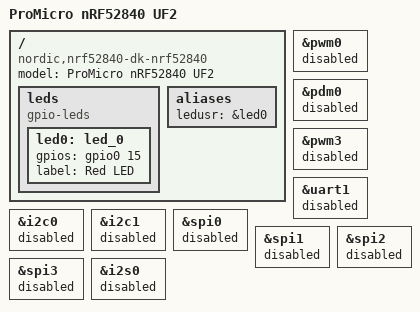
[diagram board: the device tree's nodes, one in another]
// #include <zephyr/dt-bindings/pinctrl/nrf-pinctrl.h>
// #include <nordic/nrf52840_qiaa.dtsi>

/ {
    model = "ProMicro nRF52840 UF2";
    compatible = "nordic,nrf52840-dk-nrf52840";

    leds {
        compatible = "gpio-leds";

        led0: led_0 {
            gpios = <&gpio0 15 GPIO_ACTIVE_HIGH>;
            label = "Red LED";
        };
    };

    aliases {
        ledusr = &led0;
    };
};

// &usbd {
// 	status = "disabled";
// };

&pwm0 {
    status = "disabled";
};

&pdm0 {
    status = "disabled";
};

&pwm3 {
    status = "disabled";
};

//&uart0 {
//    status = "disabled";
//};
&uart1 {
    status = "disabled";
};

&i2c0 {
    status = "disabled";
};

&i2c1 {
    status = "disabled";
};

&spi0 {
    status = "disabled";
};

&spi1 {
    status = "disabled";
};

&spi2 {
    status = "disabled";
};

&spi3 {
    status = "disabled";
};

&i2s0 {
    status = "disabled";
};


